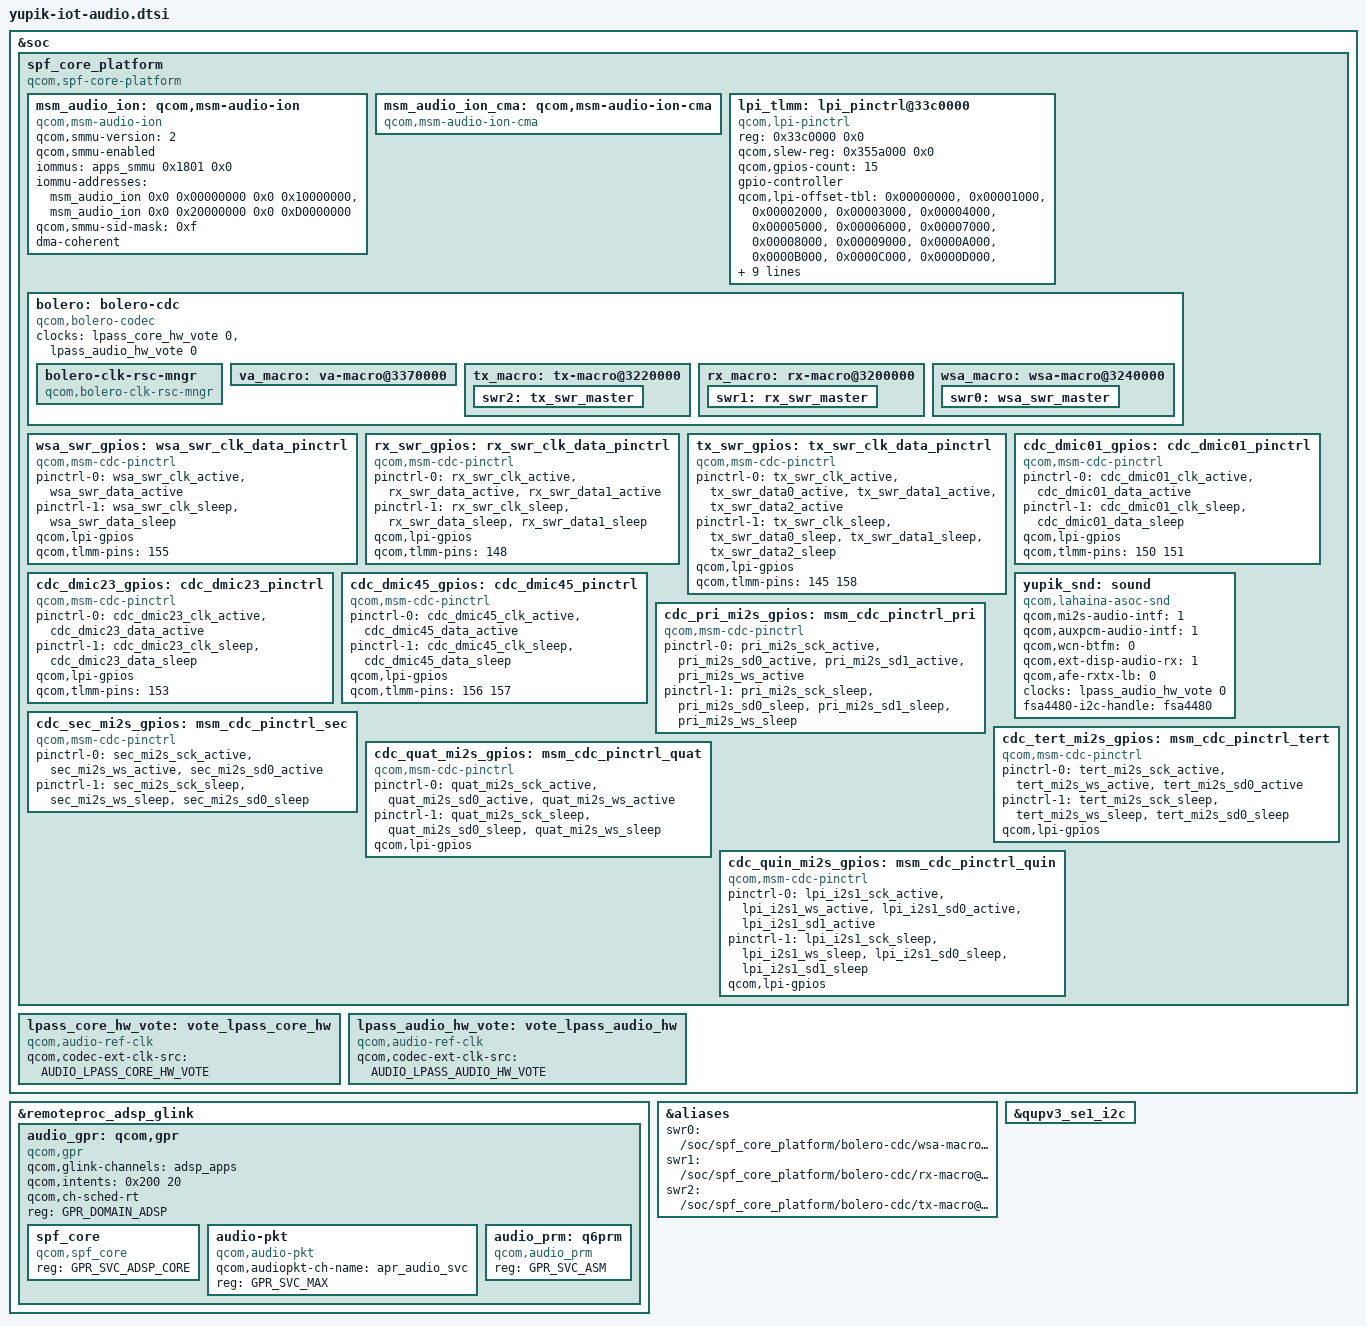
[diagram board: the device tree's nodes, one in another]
// SPDX-License-Identifier: BSD-3-Clause
/*
 * Changes from Qualcomm Technologies, Inc. are provided under the following license:
 * Copyright (c) Qualcomm Technologies, Inc. and/or its subsidiaries.
 */

#include <bindings/qcom,audio-ext-clk.h>
#include <bindings/qcom,gpr.h>
#include "msm-audio-lpass.dtsi"

&soc {
        spf_core_platform: spf_core_platform {
                compatible = "qcom,spf-core-platform";
        };

        lpass_core_hw_vote: vote_lpass_core_hw {
                compatible = "qcom,audio-ref-clk";
                qcom,codec-ext-clk-src = <AUDIO_LPASS_CORE_HW_VOTE>;
                #clock-cells = <1>;
        };

        lpass_audio_hw_vote: vote_lpass_audio_hw {
                compatible = "qcom,audio-ref-clk";
                qcom,codec-ext-clk-src = <AUDIO_LPASS_AUDIO_HW_VOTE>;
                #clock-cells = <1>;
        };
};

&remoteproc_adsp_glink {
        audio_gpr: qcom,gpr {
                compatible = "qcom,gpr";
                qcom,glink-channels = "adsp_apps";
                qcom,intents = <0x200 20>;
                qcom,ch-sched-rt;
                reg = <GPR_DOMAIN_ADSP>;

                spf_core {
                        compatible = "qcom,spf_core";
                        reg = <GPR_SVC_ADSP_CORE>;
                };

                audio-pkt {
                        compatible = "qcom,audio-pkt";
                        qcom,audiopkt-ch-name = "apr_audio_svc";
                        reg = <GPR_SVC_MAX>;
                };

                audio_prm: q6prm {
                        compatible = "qcom,audio_prm";
                        reg = <GPR_SVC_ASM>;
                };
        };
};

#include "yupik-lpi.dtsi"

&spf_core_platform {

        msm_audio_ion: qcom,msm-audio-ion {
                compatible = "qcom,msm-audio-ion";
                qcom,smmu-version = <2>;
                qcom,smmu-enabled;
                iommus = <&apps_smmu 0x1801 0x0>;
				iommu-addresses = <&msm_audio_ion 0x0 0x00000000 0x0 0x10000000>,
                                        <&msm_audio_ion 0x0 0x20000000 0x0 0xD0000000>;
                qcom,smmu-sid-mask = /bits/ 64 <0xf>;
                dma-coherent;
        };

        msm_audio_ion_cma: qcom,msm-audio-ion-cma {
                compatible = "qcom,msm-audio-ion-cma";
        };


	lpi_tlmm: lpi_pinctrl@33c0000 {
		compatible = "qcom,lpi-pinctrl";
		reg = <0x33c0000 0x0>;
		qcom,slew-reg = <0x355a000 0x0>;
		qcom,gpios-count = <15>;
		gpio-controller;
		#gpio-cells = <2>;
		qcom,lpi-offset-tbl = <0x00000000>, <0x00001000>,
				      <0x00002000>, <0x00003000>,
				      <0x00004000>, <0x00005000>,
				      <0x00006000>, <0x00007000>,
				      <0x00008000>, <0x00009000>,
				      <0x0000A000>, <0x0000B000>,
				      <0x0000C000>, <0x0000D000>,
				      <0x0000E000>;
		qcom,lpi-slew-offset-tbl = <0x00000000>, <0x00000002>,
					   <0x00000004>, <0x00000008>,
					   <0x0000000A>, <0x0000000C>,
					   <0x00000000>, <0x00000000>,
					   <0x00000000>, <0x00000000>,
					   <0x00000010>, <0x00000012>,
					   <0x00000000>, <0x00000000>,
					   <0x00000006>;

		clock-names = "lpass_core_hw_vote",
					"lpass_audio_hw_vote";
		clocks = <&lpass_core_hw_vote 0>,
				<&lpass_audio_hw_vote 0>;
	};

	bolero: bolero-cdc {
		compatible = "qcom,bolero-codec";
		clock-names = "lpass_core_hw_vote",
				"lpass_audio_hw_vote";
		clocks = <&lpass_core_hw_vote 0>,
				<&lpass_audio_hw_vote 0>;
		bolero-clk-rsc-mngr {
			compatible = "qcom,bolero-clk-rsc-mngr";
		};

		va_macro: va-macro@3370000 {
		};

		tx_macro: tx-macro@3220000 {
			swr2: tx_swr_master {
			};
		};

		rx_macro: rx-macro@3200000 {
			swr1: rx_swr_master {
			};
		};

		wsa_macro: wsa-macro@3240000 {
			swr0: wsa_swr_master {
			};
		};
	};

	wsa_swr_gpios: wsa_swr_clk_data_pinctrl {
		compatible = "qcom,msm-cdc-pinctrl";
		pinctrl-names = "aud_active", "aud_sleep";
		pinctrl-0 = <&wsa_swr_clk_active &wsa_swr_data_active>;
		pinctrl-1 = <&wsa_swr_clk_sleep &wsa_swr_data_sleep>;
		qcom,lpi-gpios;
		qcom,tlmm-pins = <155>;
		#gpio-cells = <0>;
	};

	rx_swr_gpios: rx_swr_clk_data_pinctrl {
		compatible = "qcom,msm-cdc-pinctrl";
		pinctrl-names = "aud_active", "aud_sleep";
		pinctrl-0 = <&rx_swr_clk_active &rx_swr_data_active
				&rx_swr_data1_active>;
		pinctrl-1 = <&rx_swr_clk_sleep &rx_swr_data_sleep
				&rx_swr_data1_sleep>;
		qcom,lpi-gpios;
		qcom,tlmm-pins = <148>;
		#gpio-cells = <0>;
	};

	tx_swr_gpios: tx_swr_clk_data_pinctrl {
                compatible = "qcom,msm-cdc-pinctrl";
                pinctrl-names = "aud_active", "aud_sleep";
                pinctrl-0 = <&tx_swr_clk_active &tx_swr_data0_active
                            &tx_swr_data1_active &tx_swr_data2_active>;
                pinctrl-1 = <&tx_swr_clk_sleep &tx_swr_data0_sleep
                            &tx_swr_data1_sleep &tx_swr_data2_sleep>;
                qcom,lpi-gpios;
                qcom,tlmm-pins = <145 158>;
                #gpio-cells = <0>;
        };

	cdc_dmic01_gpios: cdc_dmic01_pinctrl {
		compatible = "qcom,msm-cdc-pinctrl";
		pinctrl-names = "aud_active", "aud_sleep";
		pinctrl-0 = <&cdc_dmic01_clk_active &cdc_dmic01_data_active>;
		pinctrl-1 = <&cdc_dmic01_clk_sleep &cdc_dmic01_data_sleep>;
		qcom,lpi-gpios;
		qcom,tlmm-pins = <150 151>;
		#gpio-cells = <0>;
	};

	cdc_dmic23_gpios: cdc_dmic23_pinctrl {
		compatible = "qcom,msm-cdc-pinctrl";
		pinctrl-names = "aud_active", "aud_sleep";
		pinctrl-0 = <&cdc_dmic23_clk_active &cdc_dmic23_data_active>;
		pinctrl-1 = <&cdc_dmic23_clk_sleep &cdc_dmic23_data_sleep>;
		qcom,lpi-gpios;
		qcom,tlmm-pins = <153>;
		#gpio-cells = <0>;
	};

	cdc_dmic45_gpios: cdc_dmic45_pinctrl {
		compatible = "qcom,msm-cdc-pinctrl";
		pinctrl-names = "aud_active", "aud_sleep";
		pinctrl-0 = <&cdc_dmic45_clk_active &cdc_dmic45_data_active>;
		pinctrl-1 = <&cdc_dmic45_clk_sleep &cdc_dmic45_data_sleep>;
		qcom,lpi-gpios;
		qcom,tlmm-pins = <156 157>;
		#gpio-cells = <0>;
	};

	yupik_snd: sound {
		compatible = "qcom,lahaina-asoc-snd";
		qcom,mi2s-audio-intf = <1>;
		qcom,auxpcm-audio-intf = <1>;
		qcom,wcn-btfm = <0>;
		qcom,ext-disp-audio-rx = <1>;
		qcom,afe-rxtx-lb = <0>;

		clock-names = "lpass_audio_hw_vote";
		clocks = <&lpass_audio_hw_vote 0>;
		fsa4480-i2c-handle = <&fsa4480>;
	};

	cdc_pri_mi2s_gpios: msm_cdc_pinctrl_pri {
		compatible = "qcom,msm-cdc-pinctrl";
		pinctrl-names = "aud_active", "aud_sleep";
		pinctrl-0 = <&pri_mi2s_sck_active &pri_mi2s_sd0_active
			&pri_mi2s_sd1_active &pri_mi2s_ws_active>;
		pinctrl-1 = <&pri_mi2s_sck_sleep &pri_mi2s_sd0_sleep
			&pri_mi2s_sd1_sleep &pri_mi2s_ws_sleep>;
		#gpio-cells = <0>;
	};

	cdc_sec_mi2s_gpios: msm_cdc_pinctrl_sec {
		compatible = "qcom,msm-cdc-pinctrl";
		pinctrl-names = "aud_active", "aud_sleep";
		pinctrl-0 = <&sec_mi2s_sck_active &sec_mi2s_ws_active
				&sec_mi2s_sd0_active>;
		pinctrl-1 = <&sec_mi2s_sck_sleep &sec_mi2s_ws_sleep
				&sec_mi2s_sd0_sleep>;
		#gpio-cells = <0>;
	};

	cdc_tert_mi2s_gpios: msm_cdc_pinctrl_tert {
		compatible = "qcom,msm-cdc-pinctrl";
		pinctrl-names = "aud_active", "aud_sleep";
		pinctrl-0 = <&tert_mi2s_sck_active &tert_mi2s_ws_active
			&tert_mi2s_sd0_active>;
		pinctrl-1 = <&tert_mi2s_sck_sleep &tert_mi2s_ws_sleep
			&tert_mi2s_sd0_sleep>;
		qcom,lpi-gpios;
		#gpio-cells = <0>;
	};

	cdc_quat_mi2s_gpios: msm_cdc_pinctrl_quat {
		compatible = "qcom,msm-cdc-pinctrl";
		pinctrl-names = "aud_active", "aud_sleep";
		pinctrl-0 = <&quat_mi2s_sck_active &quat_mi2s_sd0_active
			&quat_mi2s_ws_active>;
		pinctrl-1 = <&quat_mi2s_sck_sleep &quat_mi2s_sd0_sleep
			&quat_mi2s_ws_sleep>;
		qcom,lpi-gpios;
		#gpio-cells = <0>;
	};

	cdc_quin_mi2s_gpios:  msm_cdc_pinctrl_quin {
		compatible = "qcom,msm-cdc-pinctrl";
		pinctrl-names = "aud_active", "aud_sleep";
		pinctrl-0 = <&lpi_i2s1_sck_active &lpi_i2s1_ws_active
				&lpi_i2s1_sd0_active &lpi_i2s1_sd1_active>;
		pinctrl-1 = <&lpi_i2s1_sck_sleep &lpi_i2s1_ws_sleep
				&lpi_i2s1_sd0_sleep &lpi_i2s1_sd1_sleep>;
		qcom,lpi-gpios;
		#gpio-cells = <0>;
	};
};

&aliases {
        swr0 = "/soc/spf_core_platform/bolero-cdc/wsa-macro@3240000/wsa_swr_master";
        swr1 = "/soc/spf_core_platform/bolero-cdc/rx-macro@3200000/rx_swr_master";
        swr2 = "/soc/spf_core_platform/bolero-cdc/tx-macro@3220000/tx_swr_master";
};

&qupv3_se1_i2c {
};
